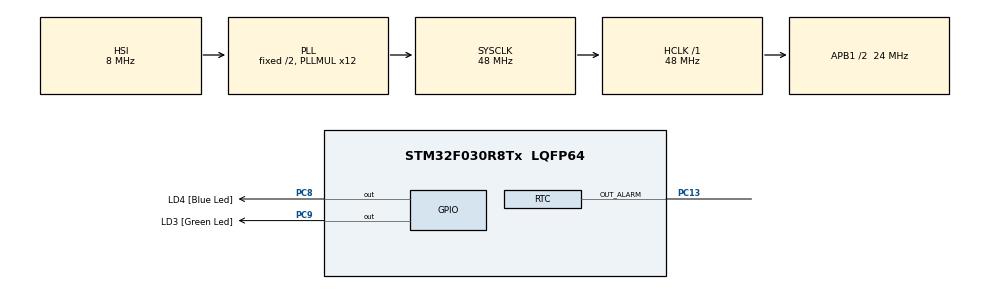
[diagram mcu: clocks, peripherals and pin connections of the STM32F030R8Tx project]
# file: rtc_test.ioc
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Mcu.Family=STM32F0
Mcu.Name=STM32F030R8Tx
Mcu.Package=LQFP64
PA13.GPIO_Label=SWDIO
PA13.Mode=Serial-WireDebug
PA13.Signal=SYS_SWDIO
PA14.GPIO_Label=SWCLK
PA14.Mode=Serial-WireDebug
PA14.Signal=SYS_SWCLK
PC13.Mode=Alarm A
PC13.Signal=RTC_OUT_ALARM
PC8.GPIO_Label=LD4 [Blue Led]
PC8.GPIO_ModeDefaultOutputPP=GPIO_MODE_OUTPUT_PP
PC8.GPIO_PuPd=GPIO_NOPULL
PC8.GPIO_Speed=GPIO_SPEED_LOW
PC8.Signal=GPIO_Output
PC9.GPIO_Label=LD3 [Green Led]
PC9.GPIO_ModeDefaultOutputPP=GPIO_MODE_OUTPUT_PP
PC9.GPIO_PuPd=GPIO_NOPULL
PC9.GPIO_Speed=GPIO_SPEED_LOW
PC9.Signal=GPIO_Output
ProjectManager.TargetToolchain=MDK-ARM V5
RCC.AHBFreq_Value=48000000
RCC.APB1CLKDivider=RCC_HCLK_DIV2
RCC.APB1Freq_Value=24000000
RCC.APB1TimFreq_Value=48000000
RCC.DATA_CACHE_ENABLE=1
RCC.HCLKFreq_Value=48000000
RCC.INSTRUCTION_CACHE_ENABLE=1
RCC.PLLMUL=RCC_PLL_MUL12
RCC.SYSCLKFreq_VALUE=48000000
RCC.SYSCLKSource=RCC_SYSCLKSOURCE_PLLCLK
RTC.AlarmDateWeekDaySel=RTC_ALARMDATEWEEKDAYSEL_WEEKDAY
RTC.Date=5
RTC.Format=FORMAT_BIN
RTC.HourFormat=RTC_HOURFORMAT_12
RTC.Hours=3
RTC.Hours_A=12
RTC.Month=RTC_MONTH_MARCH
RTC.TimeFormat=RTC_HOURFORMAT12_PM
RTC.WeekDay=RTC_WEEKDAY_SUNDAY
RTC.Year=16
board=STM32F0308-DISCO

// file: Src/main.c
/**
  ******************************************************************************
  * File Name          : main.c
  * Description        : Main program body
  ******************************************************************************
  *
  * COPYRIGHT(c) 2016 STMicroelectronics
  *
  * Redistribution and use in source and binary forms, with or without modification,
  * are permitted provided that the following conditions are met:
  *   1. Redistributions of source code must retain the above copyright notice,
  *      this list of conditions and the following disclaimer.
  *   2. Redistributions in binary form must reproduce the above copyright notice,
  *      this list of conditions and the following disclaimer in the documentation
  *      and/or other materials provided with the distribution.
  *   3. Neither the name of STMicroelectronics nor the names of its contributors
  *      may be used to endorse or promote products derived from this software
  *      without specific prior written permission.
  *
  * THIS SOFTWARE IS PROVIDED BY THE COPYRIGHT HOLDERS AND CONTRIBUTORS "AS IS"
  * AND ANY EXPRESS OR IMPLIED WARRANTIES, INCLUDING, BUT NOT LIMITED TO, THE
  * IMPLIED WARRANTIES OF MERCHANTABILITY AND FITNESS FOR A PARTICULAR PURPOSE ARE
  * DISCLAIMED. IN NO EVENT SHALL THE COPYRIGHT HOLDER OR CONTRIBUTORS BE LIABLE
  * FOR ANY DIRECT, INDIRECT, INCIDENTAL, SPECIAL, EXEMPLARY, OR CONSEQUENTIAL
  * DAMAGES (INCLUDING, BUT NOT LIMITED TO, PROCUREMENT OF SUBSTITUTE GOODS OR
  * SERVICES; LOSS OF USE, DATA, OR PROFITS; OR BUSINESS INTERRUPTION) HOWEVER
  * CAUSED AND ON ANY THEORY OF LIABILITY, WHETHER IN CONTRACT, STRICT LIABILITY,
  * OR TORT (INCLUDING NEGLIGENCE OR OTHERWISE) ARISING IN ANY WAY OUT OF THE USE
  * OF THIS SOFTWARE, EVEN IF ADVISED OF THE POSSIBILITY OF SUCH DAMAGE.
  *
  ******************************************************************************
  */
#include "stm32f0xx_hal.h"

RTC_HandleTypeDef hrtc;

/* USER CODE BEGIN PV */
/* Private variables ---------------------------------------------------------*/
RTC_TimeTypeDef sTime;
RTC_DateTypeDef sDate;
uint32_t Format,check_counter;
/* USER CODE END PV */

void SystemClock_Config(void);
static void MX_GPIO_Init(void);
static void MX_RTC_Init(void);

/* USER CODE BEGIN PFP */
/* Private function prototypes -----------------------------------------------*/

/* USER CODE END PFP */

/* USER CODE BEGIN 0 */
void delay(uint32_t x){while(x--);}
/* USER CODE END 0 */

int main(void)
{

  /* USER CODE BEGIN 1 */
check_counter = 1000;
  /* USER CODE END 1 */

  /* MCU Configuration----------------------------------------------------------*/

  /* Reset of all peripherals, Initializes the Flash interface and the Systick. */
  HAL_Init();

  /* Configure the system clock */
  SystemClock_Config();

  /* Initialize all configured peripherals */
  MX_GPIO_Init();
  MX_RTC_Init();

  /* USER CODE BEGIN 2 */
	Format = RTC_FORMAT_BCD;
	sTime.Hours = 12;
  sTime.Minutes = 12;
  sTime.Seconds = 12;
  sTime.TimeFormat = RTC_HOURFORMAT12_PM;
  sTime.DayLightSaving = RTC_DAYLIGHTSAVING_NONE;
  sTime.StoreOperation = RTC_STOREOPERATION_RESET;
  HAL_RTC_SetTime(&hrtc, &sTime, FORMAT_BIN);

  sDate.WeekDay = RTC_WEEKDAY_SUNDAY;
  sDate.Month = RTC_MONTH_MARCH;
  sDate.Date = 12;
  sDate.Year = 12;
  HAL_RTC_SetDate(&hrtc, &sDate, FORMAT_BIN);
  /* USER CODE END 2 */

  /* Infinite loop */
  while (1)
  {

  }

}

/** System Clock Configuration
*/
void SystemClock_Config(void)
{

  RCC_OscInitTypeDef RCC_OscInitStruct;
  RCC_ClkInitTypeDef RCC_ClkInitStruct;
  RCC_PeriphCLKInitTypeDef PeriphClkInit;

  RCC_OscInitStruct.OscillatorType = RCC_OSCILLATORTYPE_HSI|RCC_OSCILLATORTYPE_LSI;
  RCC_OscInitStruct.HSIState = RCC_HSI_ON;
  RCC_OscInitStruct.HSICalibrationValue = 16;
  RCC_OscInitStruct.LSIState = RCC_LSI_ON;
  RCC_OscInitStruct.PLL.PLLState = RCC_PLL_ON;
  RCC_OscInitStruct.PLL.PLLSource = RCC_PLLSOURCE_HSI;
  RCC_OscInitStruct.PLL.PLLMUL = RCC_PLL_MUL12;
  RCC_OscInitStruct.PLL.PREDIV = RCC_PREDIV_DIV1;
  HAL_RCC_OscConfig(&RCC_OscInitStruct);

  RCC_ClkInitStruct.ClockType = RCC_CLOCKTYPE_SYSCLK|RCC_CLOCKTYPE_PCLK1;
  RCC_ClkInitStruct.SYSCLKSource = RCC_SYSCLKSOURCE_PLLCLK;
  RCC_ClkInitStruct.AHBCLKDivider = RCC_SYSCLK_DIV1;
  RCC_ClkInitStruct.APB1CLKDivider = RCC_HCLK_DIV2;
  HAL_RCC_ClockConfig(&RCC_ClkInitStruct, FLASH_LATENCY_1);

  PeriphClkInit.PeriphClockSelection = RCC_PERIPHCLK_RTC;
  PeriphClkInit.RTCClockSelection = RCC_RTCCLKSOURCE_LSI;
  HAL_RCCEx_PeriphCLKConfig(&PeriphClkInit);

  HAL_SYSTICK_Config(HAL_RCC_GetHCLKFreq()/1000);

  HAL_SYSTICK_CLKSourceConfig(SYSTICK_CLKSOURCE_HCLK);

}

/* RTC init function */
void MX_RTC_Init(void)
{

  RTC_TimeTypeDef sTime;
  RTC_DateTypeDef sDate;
  RTC_AlarmTypeDef sAlarm;

    /**Initialize RTC and set the Time and Date
    */
  hrtc.Instance = RTC;
  hrtc.Init.HourFormat = RTC_HOURFORMAT_12;
  hrtc.Init.AsynchPrediv = 127;
  hrtc.Init.SynchPrediv = 255;
  hrtc.Init.OutPut = RTC_OUTPUT_ALARMA;
  hrtc.Init.OutPutPolarity = RTC_OUTPUT_POLARITY_HIGH;
  hrtc.Init.OutPutType = RTC_OUTPUT_TYPE_OPENDRAIN;
  HAL_RTC_Init(&hrtc);

  sTime.Hours = 3;
  sTime.Minutes = 0;
  sTime.Seconds = 0;
  sTime.TimeFormat = RTC_HOURFORMAT12_PM;
  sTime.DayLightSaving = RTC_DAYLIGHTSAVING_NONE;
  sTime.StoreOperation = RTC_STOREOPERATION_RESET;
  HAL_RTC_SetTime(&hrtc, &sTime, FORMAT_BIN);

  sDate.WeekDay = RTC_WEEKDAY_SUNDAY;
  sDate.Month = RTC_MONTH_MARCH;
  sDate.Date = 5;
  sDate.Year = 16;
  HAL_RTC_SetDate(&hrtc, &sDate, FORMAT_BIN);

    /**Enable the Alarm A
    */
  sAlarm.AlarmTime.Hours = 12;
  sAlarm.AlarmTime.Minutes = 0;
  sAlarm.AlarmTime.Seconds = 0;
  sAlarm.AlarmTime.TimeFormat = RTC_HOURFORMAT12_PM;
  sAlarm.AlarmTime.DayLightSaving = RTC_DAYLIGHTSAVING_NONE;
  sAlarm.AlarmTime.StoreOperation = RTC_STOREOPERATION_RESET;
  sAlarm.AlarmMask = RTC_ALARMMASK_NONE;
  sAlarm.AlarmSubSecondMask = RTC_ALARMSUBSECONDMASK_ALL;
  sAlarm.AlarmDateWeekDaySel = RTC_ALARMDATEWEEKDAYSEL_WEEKDAY;
  sAlarm.AlarmDateWeekDay = RTC_WEEKDAY_MONDAY;
  sAlarm.Alarm = RTC_ALARM_A;
  HAL_RTC_SetAlarm(&hrtc, &sAlarm, FORMAT_BIN);

}

/** Configure pins as
        * Analog
        * Input
        * Output
        * EVENT_OUT
        * EXTI
*/
void MX_GPIO_Init(void)
{

  GPIO_InitTypeDef GPIO_InitStruct;

  /* GPIO Ports Clock Enable */
  __GPIOC_CLK_ENABLE();
  __GPIOA_CLK_ENABLE();

  /*Configure GPIO pins : PC8 PC9 */
  GPIO_InitStruct.Pin = GPIO_PIN_8|GPIO_PIN_9;
  GPIO_InitStruct.Mode = GPIO_MODE_OUTPUT_PP;
  GPIO_InitStruct.Pull = GPIO_NOPULL;
  GPIO_InitStruct.Speed = GPIO_SPEED_LOW;
  HAL_GPIO_Init(GPIOC, &GPIO_InitStruct);

}

/************************ (C) COPYRIGHT STMicroelectronics *****END OF FILE****/
